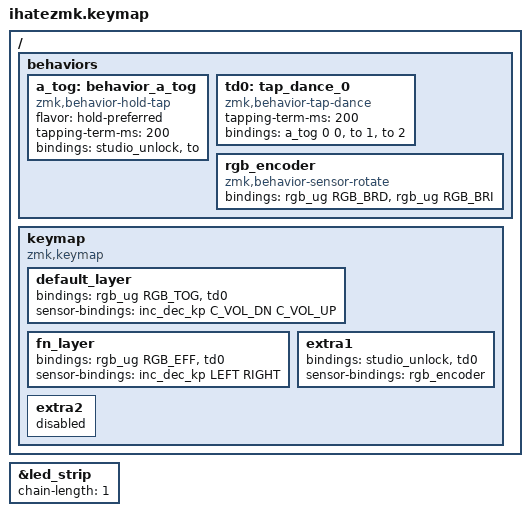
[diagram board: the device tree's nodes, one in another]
// This file was generated from a template. Edit it to match your keyboard.
// See https://zmk.dev/docs/development/hardware-integration/new-shield for more instructions.

#include <behaviors.dtsi>
#include <dt-bindings/zmk/bt.h>
#include <dt-bindings/zmk/keys.h>
#include <dt-bindings/zmk/rgb.h>

&led_strip { chain-length = <1>; };

/ {


    behaviors {
        a_tog: behavior_a_tog {
            compatible = "zmk,behavior-hold-tap";
            #binding-cells = <2>;
            flavor = "hold-preferred";
            tapping-term-ms = <200>;
            bindings = <&studio_unlock>, <&to>;
        };

        td0: tap_dance_0 {
            compatible = "zmk,behavior-tap-dance";
            #binding-cells = <0>;
            tapping-term-ms = <200>;
            bindings = <&a_tog 0 0 &to 1 &to 2>;
        };
        
        rgb_encoder: rgb_encoder {
            compatible = "zmk,behavior-sensor-rotate";
            #sensor-binding-cells = <0>;
            bindings = <&rgb_ug RGB_BRD>, <&rgb_ug RGB_BRI>;
        };
    };

    // Define a default keymap here.
    // See https://zmk.dev/docs/development/hardware-integration/new-shield#default-keymap.

    keymap {
        compatible = "zmk,keymap";

        default_layer {
            bindings = <
            &rgb_ug RGB_TOG &td0
            >;

            sensor-bindings = <
            &inc_dec_kp C_VOL_DN C_VOL_UP
            >;
        };
///////////////////////////////////
        fn_layer {
            bindings = <
            &rgb_ug RGB_EFF &td0
            >;

            sensor-bindings = <
            &inc_dec_kp LEFT RIGHT
            >;
        };
////////////////////////////////////
        extra1 { 
            bindings = <
            &studio_unlock &td0
            >;

            sensor-bindings = <
            &rgb_encoder
            >;
        };

        extra2 { 
            status = "reserved"; }
            ;
    };
};
